# ESP32-C6 register map
Vendor: ESPRESSIF SYSTEMS (SHANGHAI) CO., LTD.; Series: ESP32 C-Series; File version: 2
CPU: RV32IMC r0p0, little endian, no MPU, no FPU, 4 interrupt priority bits
Address unit: 32 bits
Registers are 32-bit, read-write, reset 0x0 unless marked. A register's access mark holds for its fields unless they carry their own. Offsets are from the block's base; [hi:lo] are bit positions; {n}, {i} and the like mark numbered series.

## SYSTIMER — System Timer
Base 0x6000A000
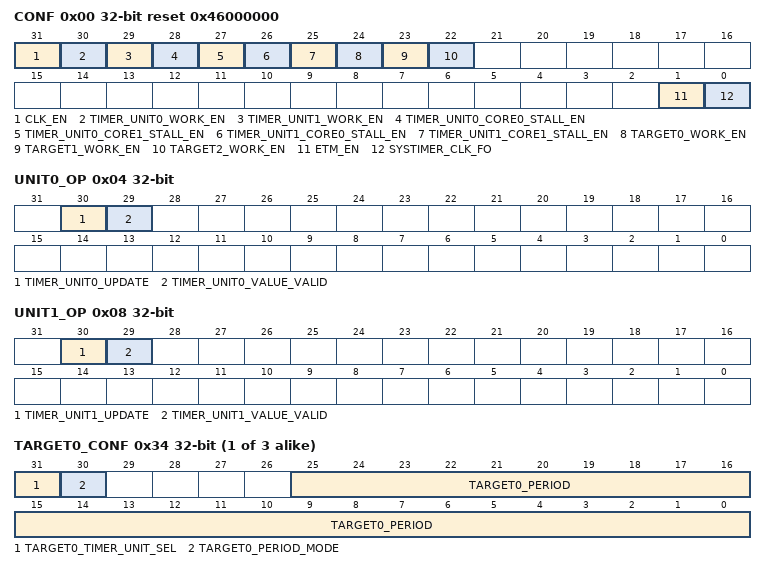
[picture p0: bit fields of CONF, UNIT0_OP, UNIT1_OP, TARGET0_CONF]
0x00 CONF reset 0x46000000 — Configure system timer clock
  [31] CLK_EN — register file clk gating
  [30] TIMER_UNIT0_WORK_EN — timer unit0 work enable
  [29] TIMER_UNIT1_WORK_EN — timer unit1 work enable
  [28] TIMER_UNIT0_CORE0_STALL_EN — If timer unit0 is stalled when core0 stalled
  [27] TIMER_UNIT0_CORE1_STALL_EN — If timer unit0 is stalled when core1 stalled
  [26] TIMER_UNIT1_CORE0_STALL_EN — If timer unit1 is stalled when core0 stalled
  [25] TIMER_UNIT1_CORE1_STALL_EN — If timer unit1 is stalled when core1 stalled
  [24] TARGET0_WORK_EN — target0 work enable
  [23] TARGET1_WORK_EN — target1 work enable
  [22] TARGET2_WORK_EN — target2 work enable
  [1] ETM_EN — enable systimer's etm task and event
  [0] SYSTIMER_CLK_FO — systimer clock force on
0x04 UNIT0_OP access per field — system timer unit0 value update register
  [30] TIMER_UNIT0_UPDATE wo — update timer_unit0
  [29] TIMER_UNIT0_VALUE_VALID ro — timer value is sync and valid
0x08 UNIT1_OP access per field — system timer unit1 value update register
  [30] TIMER_UNIT1_UPDATE wo — update timer unit1
  [29] TIMER_UNIT1_VALUE_VALID ro — timer value is sync and valid
0x0C UNIT0_LOAD_HI — system timer unit0 value high load register
  [19:0] TIMER_UNIT0_LOAD_HI — timer unit0 load high 20 bits
0x10 UNIT0_LOAD_LO — system timer unit0 value low load register
  [31:0] TIMER_UNIT0_LOAD_LO — timer unit0 load low 32 bits
0x14 UNIT1_LOAD_HI — system timer unit1 value high load register
  [19:0] TIMER_UNIT1_LOAD_HI — timer unit1 load high 20 bits
0x18 UNIT1_LOAD_LO — system timer unit1 value low load register
  [31:0] TIMER_UNIT1_LOAD_LO — timer unit1 load low 32 bits
{0x1C+8i} TARGET{i}_HI (i=0..2) — system timer comp{i} value high register
  [19:0] TIMER_TARGET{i}_HI — timer taget{i} high 20 bits
{0x20+8i} TARGET{i}_LO (i=0..2) — system timer comp{i} value low register
  [31:0] TIMER_TARGET{i}_LO — timer taget{i} low 32 bits
{0x34+4i} TARGET{i}_CONF (i=0..2) — system timer comp{i} target mode register
  [31] TARGET{i}_TIMER_UNIT_SEL — select which unit to compare
  [30] TARGET{i}_PERIOD_MODE — Set target{i} to period mode
  [25:0] TARGET{i}_PERIOD
0x40 UNIT0_VALUE_HI ro — system timer unit0 value high register
  [19:0] TIMER_UNIT0_VALUE_HI — timer read value high 20bits
0x44 UNIT0_VALUE_LO ro — system timer unit0 value low register
  [31:0] TIMER_UNIT0_VALUE_LO — timer read value low 32bits
0x48 UNIT1_VALUE_HI ro — system timer unit1 value high register
  [19:0] TIMER_UNIT1_VALUE_HI — timer read value high 20bits
0x4C UNIT1_VALUE_LO ro — system timer unit1 value low register
  [31:0] TIMER_UNIT1_VALUE_LO — timer read value low 32bits
{0x50+4i} COMP{i}_LOAD wo (i=0..2) — system timer comp{i} conf sync register
  [0] TIMER_COMP{i}_LOAD — timer comp{i} sync enable signal
0x5C UNIT0_LOAD wo — system timer unit0 conf sync register
  [0] TIMER_UNIT0_LOAD — timer unit0 sync enable signal
0x60 UNIT1_LOAD wo — system timer unit1 conf sync register
  [0] TIMER_UNIT1_LOAD — timer unit1 sync enable signal
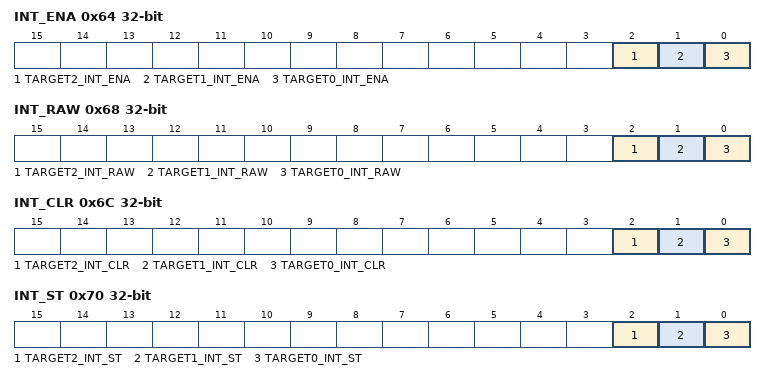
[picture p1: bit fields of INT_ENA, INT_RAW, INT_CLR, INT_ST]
0x64 INT_ENA — systimer interrupt enable register
  [2] TARGET2_INT_ENA — interupt2 enable
  [1] TARGET1_INT_ENA — interupt1 enable
  [0] TARGET0_INT_ENA — interupt0 enable
0x68 INT_RAW ro — systimer interrupt raw register
  [2] TARGET2_INT_RAW — interupt2 raw
  [1] TARGET1_INT_RAW — interupt1 raw
  [0] TARGET0_INT_RAW — interupt0 raw
0x6C INT_CLR wo — systimer interrupt clear register
  [2] TARGET2_INT_CLR — interupt2 clear
  [1] TARGET1_INT_CLR — interupt1 clear
  [0] TARGET0_INT_CLR — interupt0 clear
0x70 INT_ST ro — systimer interrupt status register
  [2] TARGET2_INT_ST — interupt2 status
  [1] TARGET1_INT_ST — interupt1 status
  [0] TARGET0_INT_ST — interupt0 status
{0x74+8i} REAL_TARGET{i}_LO ro (i=0..2) — system timer comp{i} actual target value low register
  [31:0] TARGET{i}_LO_RO — actual target value value low 32bits
{0x78+8i} REAL_TARGET{i}_HI ro (i=0..2) — system timer comp{i} actual target value high register
  [19:0] TARGET{i}_HI_RO — actual target value value high 20bits
0xFC DATE reset 0x2201073 — system timer version control register
  [31:0] DATE — systimer register version
